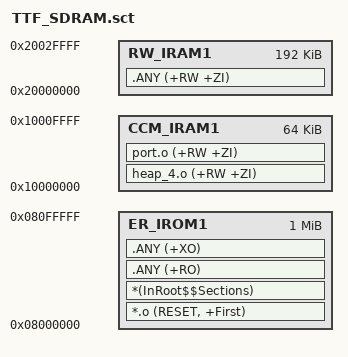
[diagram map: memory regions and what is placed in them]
; *************************************************************
; *** Scatter-Loading Description File generated by uVision ***
; *************************************************************

LR_IROM1 0x08000000 0x00100000  {    ; load region size_region
  ER_IROM1 0x08000000 0x00100000  {  ; load address = execution address
   *.o (RESET, +First)
   *(InRoot$$Sections)
   .ANY (+RO)
   .ANY (+XO)
  }
  RW_IRAM1 0x20000000 0x00030000  {  ; RW data
   .ANY (+RW +ZI)
  }
  CCM_IRAM1 0x10000000 0x00010000  {  ; FreeRTOS
   heap_4.o (+RW +ZI)
   port.o (+RW +ZI)
  }
;  RW_ERAM1 0xD0A00000 0x01200000 {  ; 外部SDRAM，从10MB处开始，大小18MB，避开LCD显存
;   *.o(HEAP)					;选择堆区
;   ;.ANY (EXRAM)				;选择EXRAM节区
  }
}

